# NAMES register map
Registers are 32-bit, read-write, no defined reset value unless marked. A register's access mark holds for its fields unless they carry their own. Offsets are from the block's base; lines under a group give offsets from that group; [hi:lo] are bit positions; {n}, {i} and the like mark numbered series; 'fields as' and 'values as' point back to an identical list; <NAME> marks a mode.

## Memory map
0x40000000 WORDS — Registers and clusters named as keywords, built-in types, and words that are names by position.
0x40001000 match — A peripheral keeps its case, and `match` is a keyword.
0x40002000 MEET — Names that meet after their case is converted.
0x40003000 CHARS — Characters no identifier has, and a leading digit.
0x40004000 INDICES — Indices in names.
{0x50000000+0x1000*n} UART{n} (n=0..1) — A peripheral type and its module from a name with `{n}`.
0x50010000 uart — Named as the module of UART{n}: renamed.
0x50020000 3DES — A peripheral that starts with a digit.
0x50030000 CORE
0x50040000 FIELD_WORDS — Fields named as words of Erebos, and enums whose variants are.
0x50050000 RTC_CNTL — A register named as its peripheral: its struct meets the peripheral type.

## WORDS — Registers and clusters named as keywords, built-in types, and words that are names by position.
Base 0x40000000
0x00 CONTINUE
0x04 MATCH
0x08 IN
0x0C READ
0x10 WRITE
0x14 STEP
0x18 AT
0x1C OVER
0x20 CORE
0x24 U8
0x28 BOOL
0x100 LOOP group
  0x00 CONTINUE
0x200 IN group
  0x00 READ
0x300 READ group
  0x00 WRITE

## match — A peripheral keeps its case, and `match` is a keyword.
Base 0x40001000
Same registers: 3DES 0x50020000, CORE 0x50030000
0x00 R

## MEET — Names that meet after their case is converted.
Base 0x40002000
0x00 FOO
0x04 foo
0x08 Foo
0x0C BAR_
0x10 bar
0x100 SUB group
  0x00 CTRL
0x200 sub group
  0x00 CTRL

## CHARS — Characters no identifier has, and a leading digit.
Base 0x40003000
0x00 A.B
0x04 C-D
0x08 E  F
0x0C 2FA
0x100 7.UP group
  0x00 R

## INDICES — Indices in names.
Base 0x40004000
0x00 ITEM[{i}] (i=2..3; step 0x4)
0x10 CH{x}_CONF0 (x=A,B; step 0x4)
{0x20+4i} {i}_LEADING (i=0..1)
{0x30+4i} DUP{i} (i=0..1)
0x40 DUP0 — Meets the first element of DUP%s.

## UART{n} — A peripheral type and its module from a name with `{n}`.
Base 0x50000000; array of 2, step 0x1000
Same registers: uart 0x50010000
0x00 CONF

## FIELD_WORDS — Fields named as words of Erebos, and enums whose variants are.
Base 0x50040000
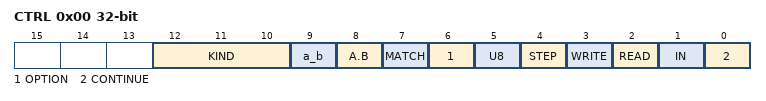
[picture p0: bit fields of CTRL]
0x00 CTRL
  [12:10] KIND
    0=OPTION; 1=RESULT; 2=BOOL; 3=U8; 4=NONE; 5=1MHZ; 6=A.B; 7=a_b
  [9] a_b — Meets A.B once its name is converted.
  [8] A.B
  [7] MATCH
  [6] OPTION
  [5] U8
  [4] STEP
  [3] WRITE
  [2] READ
  [1] IN
  [0] CONTINUE

## RTC_CNTL — A register named as its peripheral: its struct meets the peripheral type.
Base 0x50050000
0x00 RTC_CNTL
  [1:0] MODE
    0=OFF; 1=ON
